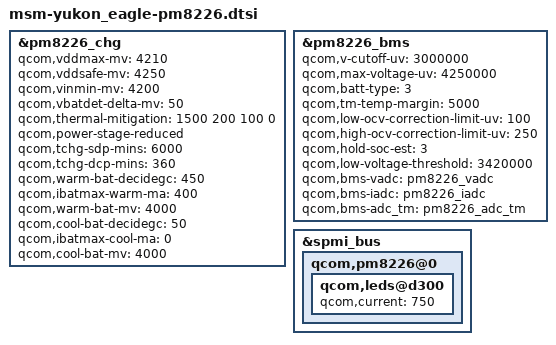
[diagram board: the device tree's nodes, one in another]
/* Copyright (c) 2012-2014, The Linux Foundation. All rights reserved.
 *
 * This program is free software; you can redistribute it and/or modify
 * it under the terms of the GNU General Public License version 2 and
 * only version 2 as published by the Free Software Foundation.
 *
 * This program is distributed in the hope that it will be useful,
 * but WITHOUT ANY WARRANTY; without even the implied warranty of
 * MERCHANTABILITY or FITNESS FOR A PARTICULAR PURPOSE.  See the
 * GNU General Public License for more details.
 */

/include/ "msm8226-yukon_eagle-regulator.dtsi"

&pm8226_chg {
	qcom,vddmax-mv = <4210>;
	qcom,vddsafe-mv = <4250>;
	qcom,vinmin-mv = <4200>;
	qcom,vbatdet-delta-mv = <50>;
	qcom,thermal-mitigation = <1500 200 100 0>;
	qcom,power-stage-reduced;
	qcom,tchg-sdp-mins = <6000>;
	qcom,tchg-dcp-mins = <360>;
	qcom,warm-bat-decidegc = <450>;
	qcom,ibatmax-warm-ma = <400>;
	qcom,warm-bat-mv = <4000>;
	qcom,cool-bat-decidegc = <50>;
	qcom,ibatmax-cool-ma = <0>;
	qcom,cool-bat-mv = <4000>;
};

&pm8226_bms {
	qcom,v-cutoff-uv = <3000000>;
	qcom,max-voltage-uv = <4250000>;
	qcom,batt-type = <3>;
	qcom,tm-temp-margin = <5000>;
	qcom,low-ocv-correction-limit-uv = <100>;
	qcom,high-ocv-correction-limit-uv = <250>;
	qcom,hold-soc-est = <3>;
	qcom,low-voltage-threshold = <3420000>;
	qcom,bms-vadc = <&pm8226_vadc>;
	qcom,bms-iadc = <&pm8226_iadc>;
	qcom,bms-adc_tm = <&pm8226_adc_tm>;
};

&spmi_bus {
	qcom,pm8226@0 {
		qcom,leds@d300 {
			qcom,current = <750>;
			};
		};
};

